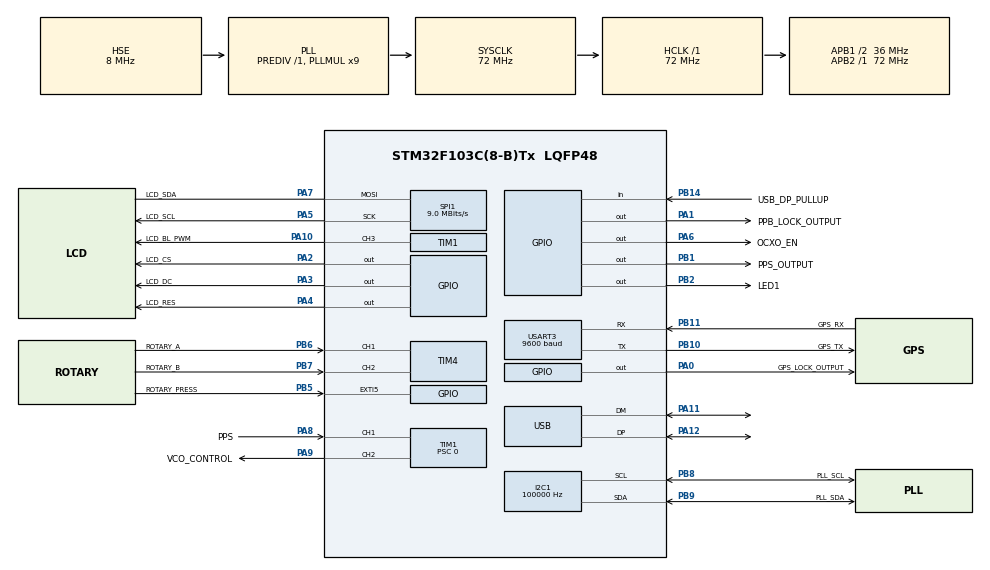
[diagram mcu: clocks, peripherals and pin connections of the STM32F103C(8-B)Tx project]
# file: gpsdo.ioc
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Dma.Request0=USART3_RX
Dma.Request1=USART3_TX
Dma.USART3_RX.0.Direction=DMA_PERIPH_TO_MEMORY
Dma.USART3_RX.0.Instance=DMA1_Channel3
Dma.USART3_RX.0.MemDataAlignment=DMA_MDATAALIGN_BYTE
Dma.USART3_RX.0.MemInc=DMA_MINC_ENABLE
Dma.USART3_RX.0.Mode=DMA_NORMAL
Dma.USART3_RX.0.PeriphDataAlignment=DMA_PDATAALIGN_BYTE
Dma.USART3_RX.0.PeriphInc=DMA_PINC_DISABLE
Dma.USART3_RX.0.Priority=DMA_PRIORITY_MEDIUM
Dma.USART3_TX.1.Direction=DMA_MEMORY_TO_PERIPH
Dma.USART3_TX.1.Instance=DMA1_Channel2
Dma.USART3_TX.1.MemDataAlignment=DMA_MDATAALIGN_BYTE
Dma.USART3_TX.1.MemInc=DMA_MINC_ENABLE
Dma.USART3_TX.1.Mode=DMA_NORMAL
Dma.USART3_TX.1.PeriphDataAlignment=DMA_PDATAALIGN_BYTE
Dma.USART3_TX.1.PeriphInc=DMA_PINC_DISABLE
Dma.USART3_TX.1.Priority=DMA_PRIORITY_LOW
I2C1.ClockSpeed=100000
Mcu.Family=STM32F1
Mcu.Name=STM32F103C(8-B)Tx
Mcu.Package=LQFP48
NVIC.DMA1_Channel2_IRQn=true\:0\:0\:false\:false\:true\:false\:true\:true
NVIC.DMA1_Channel3_IRQn=true\:0\:0\:false\:false\:true\:false\:true\:true
NVIC.EXTI9_5_IRQn=true\:0\:0\:false\:false\:true\:true\:true\:true
NVIC.PriorityGroup=NVIC_PRIORITYGROUP_4
NVIC.TIM1_CC_IRQn=true\:0\:0\:false\:false\:true\:true\:true\:true
NVIC.TIM1_UP_IRQn=true\:0\:0\:false\:false\:true\:true\:true\:true
NVIC.TIM2_IRQn=true\:0\:0\:false\:false\:true\:true\:true\:true
NVIC.USART3_IRQn=true\:0\:0\:false\:false\:true\:true\:true\:true
NVIC.USB_LP_CAN1_RX0_IRQn=true\:0\:0\:false\:false\:true\:false\:true\:true
PA0-WKUP.GPIO_Label=GPS_LOCK_OUTPUT
PA0-WKUP.PinState=GPIO_PIN_SET
PA0-WKUP.Signal=GPIO_Output
PA1.GPIO_Label=PPB_LOCK_OUTPUT
PA1.PinState=GPIO_PIN_SET
PA1.Signal=GPIO_Output
PA10.GPIO_Label=LCD_BL_PWM
PA10.GPIO_ModeDefaultPP=GPIO_MODE_AF_OD
PA10.Signal=S_TIM1_CH3
PA11.Mode=Device
PA11.Signal=USB_DM
PA12.Mode=Device
PA12.Signal=USB_DP
PA13.Mode=Serial_Wire
PA13.Signal=SYS_JTMS-SWDIO
PA14.Mode=Serial_Wire
PA14.Signal=SYS_JTCK-SWCLK
PA2.GPIO_Label=LCD_CS
PA2.GPIO_Speed=GPIO_SPEED_FREQ_LOW
PA2.PinState=GPIO_PIN_SET
PA2.Signal=GPIO_Output
PA3.GPIO_Label=LCD_DC
PA3.GPIO_Speed=GPIO_SPEED_FREQ_HIGH
PA3.PinState=GPIO_PIN_SET
PA3.Signal=GPIO_Output
PA4.GPIO_Label=LCD_RES
PA4.PinState=GPIO_PIN_SET
PA4.Signal=GPIO_Output
PA5.GPIO_Label=LCD_SCL
PA5.GPIO_Speed=GPIO_SPEED_FREQ_HIGH
PA5.Mode=Simplex_Bidirectional_Master
PA5.Signal=SPI1_SCK
PA6.GPIO_Label=OCXO_EN
PA6.PinState=GPIO_PIN_SET
PA6.Signal=GPIO_Output
PA7.GPIO_Label=LCD_SDA
PA7.GPIO_Speed=GPIO_SPEED_FREQ_HIGH
PA7.Mode=Simplex_Bidirectional_Master
PA7.Signal=SPI1_MOSI
PA8.GPIO_Label=PPS
PA8.GPIO_PuPd=GPIO_PULLDOWN
PA8.Signal=S_TIM1_CH1
PA9.GPIO_Label=VCO_CONTROL
PA9.GPIO_ModeDefaultPP=GPIO_MODE_AF_OD
PA9.Signal=S_TIM1_CH2
PB1.GPIO_Label=PPS_OUTPUT
PB1.Signal=GPIO_Output
PB10.GPIO_Label=GPS_TX
PB10.GPIO_Speed=GPIO_SPEED_FREQ_HIGH
PB10.Mode=Asynchronous
PB10.Signal=USART3_TX
PB11.GPIO_Label=GPS_RX
PB11.GPIO_PuPd=GPIO_PULLUP
PB11.Mode=Asynchronous
PB11.Signal=USART3_RX
PB14.GPIO_Label=USB_DP_PULLUP
PB14.Signal=GPIO_Input
PB2.GPIO_Label=LED1
PB2.Signal=GPIO_Output
PB5.GPIO_Label=ROTARY_PRESS
PB5.GPIO_ModeDefaultEXTI=GPIO_MODE_IT_RISING_FALLING
PB5.GPIO_PuPd=GPIO_PULLUP
PB5.Signal=GPXTI5
PB6.GPIO_Label=ROTARY_A
PB6.GPIO_PuPd=GPIO_PULLUP
PB6.Signal=S_TIM4_CH1
PB7.GPIO_Label=ROTARY_B
PB7.GPIO_PuPd=GPIO_PULLUP
PB7.Signal=S_TIM4_CH2
PB8.GPIO_Label=PLL_SCL
PB8.GPIO_Speed=GPIO_SPEED_FREQ_LOW
PB8.Mode=I2C
PB8.Signal=I2C1_SCL
PB9.GPIO_Label=PLL_SDA
PB9.GPIO_Speed=GPIO_SPEED_FREQ_LOW
PB9.Mode=I2C
PB9.Signal=I2C1_SDA
PD0-OSC_IN.Mode=HSE-External-Clock-Source
PD0-OSC_IN.Signal=RCC_OSC_IN
PD1-OSC_OUT.Mode=HSE-External-Clock-Source
PD1-OSC_OUT.Signal=RCC_OSC_OUT
ProjectManager.HeapSize=0x200
ProjectManager.StackSize=0x600
ProjectManager.TargetToolchain=CMake
RCC.AHBFreq_Value=72000000
RCC.APB1CLKDivider=RCC_HCLK_DIV2
RCC.APB1Freq_Value=36000000
RCC.APB1TimFreq_Value=72000000
RCC.APB2Freq_Value=72000000
RCC.APB2TimFreq_Value=72000000
RCC.HCLKFreq_Value=72000000
RCC.HSE_Timout=1500
RCC.PLLMUL=RCC_PLL_MUL9
RCC.PLLSourceVirtual=RCC_PLLSOURCE_HSE
RCC.SYSCLKFreq_VALUE=72000000
RCC.SYSCLKSource=RCC_SYSCLKSOURCE_PLLCLK
RCC.USBFreq_Value=48000000
RCC.USBPrescaler=RCC_USBCLKSOURCE_PLL_DIV1_5
SH.S_TIM1_CH1.0=TIM1_CH1,Input_Capture1_from_TI1
SH.S_TIM1_CH2.0=TIM1_CH2,PWM Generation2 CH2
SH.S_TIM1_CH3.0=TIM1_CH3,PWM Generation3 CH3
SH.S_TIM4_CH1.0=TIM4_CH1,Encoder_Interface
SH.S_TIM4_CH2.0=TIM4_CH2,Encoder_Interface
SPI1.BaudRatePrescaler=SPI_BAUDRATEPRESCALER_8
SPI1.CalculateBaudRate=9.0 MBits/s
SPI1.Direction=SPI_DIRECTION_1LINE
SPI1.Mode=SPI_MODE_MASTER
SPI1.VirtualType=VM_MASTER
TIM1.AutoReloadPreload=TIM_AUTORELOAD_PRELOAD_DISABLE
TIM1.AutomaticOutput=TIM_AUTOMATICOUTPUT_DISABLE
TIM1.BreakState=TIM_BREAK_DISABLE
TIM1.Channel-Input_Capture1_from_TI1=TIM_CHANNEL_1
TIM1.Channel-PWM\ Generation2\ CH2=TIM_CHANNEL_2
TIM1.Channel-PWM\ Generation3\ CH3=TIM_CHANNEL_3
TIM1.ClockDivision=TIM_CLOCKDIVISION_DIV1
TIM1.CounterMode=TIM_COUNTERMODE_UP
TIM1.ICFilter_CH1=0
TIM1.OCFastMode_PWM-PWM\ Generation2\ CH2=TIM_OCFAST_ENABLE
TIM1.OCFastMode_PWM-PWM\ Generation3\ CH3=TIM_OCFAST_ENABLE
TIM1.Period=65535
TIM1.Prescaler=0
TIM1.Pulse-PWM\ Generation2\ CH2=0
TIM1.Pulse-PWM\ Generation3\ CH3=65535
TIM2.Period=9999
TIM2.Prescaler=7199
TIM4.IC1Filter=15
TIM4.IC2Filter=15
USART3.BaudRate=9600
USART3.VirtualMode=VM_ASYNC
USB_DEVICE.APP_RX_DATA_SIZE=256
USB_DEVICE.CLASS_NAME_FS=CDC
USB_DEVICE.MANUFACTURER_STRING=GPSDO
USB_DEVICE.PRODUCT_STRING_CDC_FS=Micro-DO
USB_DEVICE.USBD_MAX_STR_DESC_SIZ=64
USB_DEVICE.USBD_SELF_POWERED=0
USB_DEVICE.VirtualMode=Cdc
USB_DEVICE.VirtualModeFS=Cdc_FS
VP_TIM1_VS_ClockSourceINT.Mode=Internal
VP_TIM2_VS_ClockSourceINT.Mode=Internal
VP_USB_DEVICE_VS_USB_DEVICE_CDC_FS.Mode=CDC_FS
board=custom

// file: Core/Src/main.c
/* USER CODE BEGIN Header */
/**
  ******************************************************************************
  * @file           : main.c
  * @brief          : Main program body
  ******************************************************************************
  * @attention
  *
  * Copyright (c) 2026 STMicroelectronics.
  * All rights reserved.
  *
  * This software is licensed under terms that can be found in the LICENSE file
  * in the root directory of this software component.
  * If no LICENSE file comes with this software, it is provided AS-IS.
  *
  ******************************************************************************
  */
/* USER CODE END Header */
#include "main.h"
#include "dma.h"
#include "i2c.h"
#include "spi.h"
#include "tim.h"
#include "usart.h"
#include "usb_device.h"
#include "gpio.h"

/* USER CODE BEGIN PD */
void init_ext_clock();
void gpsdo();
/* USER CODE END PD */

void SystemClock_Config(void);

int main(void)
{

  /* MCU Configuration--------------------------------------------------------*/

  /* Reset of all peripherals, Initializes the Flash interface and the Systick. */
  HAL_Init();

  /* USER CODE BEGIN Init */
  init_ext_clock();
  /* USER CODE END Init */

  /* Configure the system clock */
  SystemClock_Config();

  /* Initialize all configured peripherals */
  MX_GPIO_Init();
  MX_DMA_Init();
  MX_USART3_UART_Init();
  MX_TIM1_Init();
  MX_TIM2_Init();
  MX_I2C1_Init();
  MX_SPI1_Init();
  MX_TIM4_Init();
  MX_USB_DEVICE_Init();
  /* USER CODE BEGIN 2 */
  gpsdo();
  /* USER CODE END 2 */

  /* Infinite loop */
  while (1)
  {

  }
}

void SystemClock_Config(void)
{
  RCC_OscInitTypeDef RCC_OscInitStruct = {0};
  RCC_ClkInitTypeDef RCC_ClkInitStruct = {0};
  RCC_PeriphCLKInitTypeDef PeriphClkInit = {0};

  /** Initializes the RCC Oscillators according to the specified parameters
  * in the RCC_OscInitTypeDef structure.
  */
  RCC_OscInitStruct.OscillatorType = RCC_OSCILLATORTYPE_HSE;
  RCC_OscInitStruct.HSEState = RCC_HSE_ON;
  RCC_OscInitStruct.HSEPredivValue = RCC_HSE_PREDIV_DIV1;
  RCC_OscInitStruct.HSIState = RCC_HSI_ON;
  RCC_OscInitStruct.PLL.PLLState = RCC_PLL_ON;
  RCC_OscInitStruct.PLL.PLLSource = RCC_PLLSOURCE_HSE;
  RCC_OscInitStruct.PLL.PLLMUL = RCC_PLL_MUL9;
  if (HAL_RCC_OscConfig(&RCC_OscInitStruct) != HAL_OK)
  {
    Error_Handler();
  }

  /** Initializes the CPU, AHB and APB buses clocks
  */
  RCC_ClkInitStruct.ClockType = RCC_CLOCKTYPE_HCLK|RCC_CLOCKTYPE_SYSCLK
                              |RCC_CLOCKTYPE_PCLK1|RCC_CLOCKTYPE_PCLK2;
  RCC_ClkInitStruct.SYSCLKSource = RCC_SYSCLKSOURCE_PLLCLK;
  RCC_ClkInitStruct.AHBCLKDivider = RCC_SYSCLK_DIV1;
  RCC_ClkInitStruct.APB1CLKDivider = RCC_HCLK_DIV2;
  RCC_ClkInitStruct.APB2CLKDivider = RCC_HCLK_DIV1;

  if (HAL_RCC_ClockConfig(&RCC_ClkInitStruct, FLASH_LATENCY_2) != HAL_OK)
  {
    Error_Handler();
  }
  PeriphClkInit.PeriphClockSelection = RCC_PERIPHCLK_USB;
  PeriphClkInit.UsbClockSelection = RCC_USBCLKSOURCE_PLL_DIV1_5;
  if (HAL_RCCEx_PeriphCLKConfig(&PeriphClkInit) != HAL_OK)
  {
    Error_Handler();
  }
}

void Error_Handler(void)
{
  __disable_irq();
  while (1)
  {
  }
}
